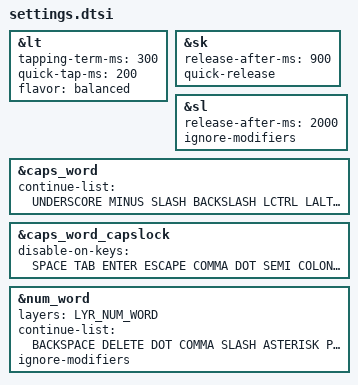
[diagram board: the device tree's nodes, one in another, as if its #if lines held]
// Make sure this file is included before all other files

/*
 * Layer Tap Settings
 */
&lt {
    // Increase layer tap time
    tapping-term-ms = <300>;

    // Quickly tap-tap-holding the lt button will repeat the tap behavior
    // For example enter-enter-hold, will output multiple enter while you
    // keep holding the key.
    // But holding enter without double tapping, will activate the layer.
     quick-tap-ms = <200>;

     flavor = "balanced";
};

/*
 * Sticky Key Settings
 */
&sk {
    release-after-ms = <900>;   // auto release after 0.6s
    // Deactivate shift on press of next key instead of on release
    // to prevent capitalization of multiple characters when rolling
    // keys (such as `ST`).
    quick-release;
};

/*
 * Sticky Layer Settings
 */
&sl {
    release-after-ms = <2000>;  // auto release after 2s
    ignore-modifiers;           // allow chording sticky mods & layers
};

/*
 * Caps Word Settings
 */
&caps_word {
    // Allow caps word to continue even when minus or underscore
    // are pressed.
    // Also prevent mod presses from cancelling caps word.
    continue-list = <
      UNDERSCORE MINUS
      SLASH BACKSLASH
      LCTRL LALT LGUI LSHFT
      RCTRL RALT RGUI RSHFT
      BACKSPACE DELETE
    >;
    #ifdef HAS_UROB
        /delete-property/ ignore-modifiers;
    #endif
};

#ifdef HAS_CAPSLOCK
    &caps_word_capslock {
        disable-on-keys = <
            SPACE TAB ENTER ESCAPE
            COMMA DOT SEMI COLON QUESTION EXCLAMATION
            SLASH BACKSLASH SINGLE_QUOTE DOUBLE_QUOTES GRAVE
            LPAR RPAR LBKT RBKT LBRC RBRC LT GT
        >;
    };
#endif

#ifdef HAS_UROB
    &num_word {
        layers = <LYR_NUM_WORD>;
        continue-list = <
            BACKSPACE DELETE DOT COMMA
            SLASH ASTERISK PLUS MINUS EQUAL DOLLAR
            RS(SPACE)
        >;
        ignore-modifiers;  // modifiers don't deactivate the layer
    };
#endif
